# MWPR1516 register map
Vendor: Freescale Semiconductor, Inc.; Series: Kinetis; File version: 1.6
CPU: CM0PLUS r0p0, little endian, no MPU, no FPU, VTOR, 2 interrupt priority bits
Registers are 8-bit, read-write, reset 0x0 unless marked. A register's access mark holds for its fields unless they carry their own. Offsets are from the block's base; [hi:lo] are bit positions; {n}, {i} and the like mark numbered series; 'fields as' and 'values as' point back to an identical list.

## ICS — Clock management
Base 0x40064000; register names take the prefix ICS_
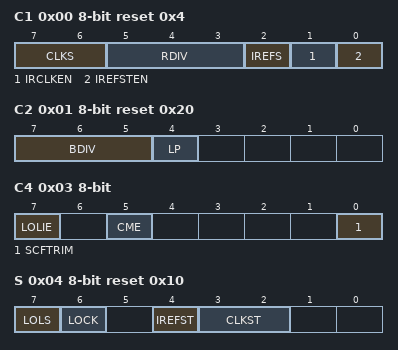
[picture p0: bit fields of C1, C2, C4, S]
0x00 C1 reset 0x4 — ICS Control Register 1
  [7:6] CLKS — Clock Source Select
    0=Output of FLL is selected; 1=Internal reference clock is selected; 2=External reference clock is selected; 3=Reserved, defaults to 00
  [5:3] RDIV — Reference Divider
  [2] IREFS — Internal Reference Select
    0=External reference clock is selected; 1=Internal reference clock is selected
  [1] IRCLKEN — Internal Reference Clock Enable
    0=ICSIRCLK is inactive; 1=ICSIRCLK is active
  [0] IREFSTEN — Internal Reference Stop Enable
    0=Internal reference clock is disabled in Stop mode; 1=Internal reference clock stays enabled in Stop mode if IRCLKEN is set, or if ICS is in FEI, FBI, or FBILP mode before entering Stop
0x01 C2 reset 0x20 — ICS Control Register 2
  [7:5] BDIV — Bus Frequency Divider
    0=Encoding 0-Divides the selected clock by 1; 1=Encoding 1-Divides the selected clock by 2 (reset default); 2=Encoding 2-Divides the selected clock by 4; 3=Encoding 3-Divides the selected clock by 8; 4=Encoding 4-Divides the selected clock by 16; 5=Encoding 5-Divides the selected clock by 32; 6=Encoding 6-Divides the selected clock by 64; 7=Encoding 7-Divides the selected clock by 128
  [4] LP — Low Power Select
    0=FLL is not disabled in bypass mode; 1=FLL is disabled in bypass modes unless debug is active
0x02 C3 reset not defined — ICS Control Register 3
  [7:0] SCTRIM — Slow Internal Reference Clock Trim Setting
0x03 C4 (reset mask 0xFE) — ICS Control Register 4
  [7] LOLIE — Loss of Lock Interrupt
    0=No request on loss of lock; 1=Generates an interrupt request on loss of lock
  [5] CME — Clock Monitor Enable
    0=Clock monitor is disabled; 1=Generates a reset request on loss of external clock
  [0] SCFTRIM — Slow Internal Reference Clock Fine Trim
0x04 S reset 0x10 — ICS Status Register
  [7] LOLS — Loss of Lock Status
    0=FLL has not lost lock since LOLS was last cleared; 1=FLL has lost lock since LOLS was last cleared
  [6] LOCK ro — Lock Status
    0=FLL is currently unlocked; 1=FLL is currently locked
  [4] IREFST ro — Internal Reference Status
    0=Source of reference clock is external clock; 1=Source of reference clock is internal clock
  [3:2] CLKST ro — Clock Mode Status
    0=Output of FLL is selected; 1=FLL Bypassed, internal reference clock is selected; 2=FLL Bypassed, external reference clock is selected

## OSC — Oscillator
Base 0x40065000; register names take the prefix OSC_
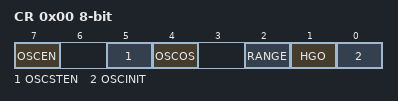
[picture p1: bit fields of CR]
0x00 CR — OSC Control Register
  [7] OSCEN — OSC Enable
    0=OSC module is disabled; 1=OSC module is enabled
  [5] OSCSTEN — OSC Enable in Stop mode
    0=OSC clock is disabled in Stop mode; 1=OSC clock stays enabled in Stop mode
  [4] OSCOS — OSC Output Select
    0=External clock source from EXTAL pin is selected; 1=Oscillator clock source is selected
  [2] RANGE — Frequency Range Select
    0=Low frequency range of 32 kHz; 1=High frequency range of 4-24 MHz
  [1] HGO — High Gain Oscillator Select
    0=Low-power mode; 1=High-gain mode
  [0] OSCINIT ro — OSC Initialization
    0=Oscillator initialization is not complete; 1=Oscillator initialization is completed

## LDO — Low Dropout Regulator
Base 0x40070000; register names take the prefix LDO_
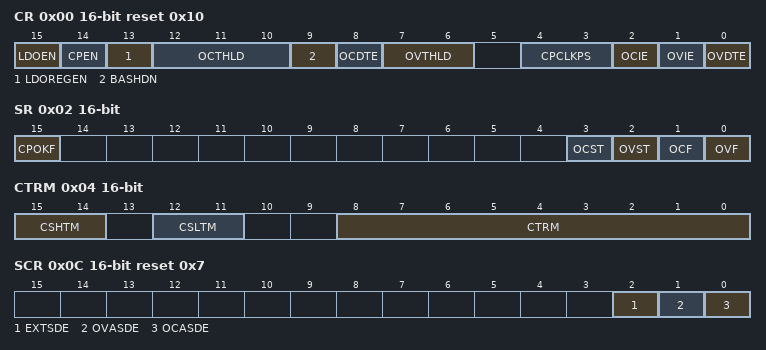
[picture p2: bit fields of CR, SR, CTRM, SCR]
0x00 CR 16-bit reset 0x10 — Control Register
  [15] LDOEN — LDO controller Enable
    0=LDO controller is disabled; 1=LDO controller is enabled
  [14] CPEN — Charge Pump Enable
    0=Charge pump is disabled; 1=Charge pump is enabled
  [13] LDOREGEN — LDO internal Regulator Enable
    0=LDO regulator is disabled; 1=LDO regulator is enabled
  [12:10] OCTHLD — Overcurrent Threshold Selection
    {v}=Level {v} (v=0..7)
  [9] BASHDN — Block the Automatic Shutdown
    0=Allows the automatically shutting down the power FET when OVP event occurs; 1=Blocks the automatic shutdown function from hard-block part when OVP event occurs. Software takes it over to shut down the external power FET.
  [8] OCDTE — Overcurrent Detection Enable
    0=Overcurrent detection is disabled; 1=Overcurrent detection is enabled
  [7:6] OVTHLD — Overvoltage Threshold Selection
    {v}=Level {v} (v=0..3)
  [4:3] CPCLKPS — Prescaler bits of the Clock to be divided for Charge Pump
    0=The division factor is 4; 1=The division factor is 8; 2=The division factor is 16; 3=The division factor is 32
  [2] OCIE — Overcurrent Interrupt Enable
    0=No interrupt gets asserted when the current loop output is over the current limit; 1=An interrupt gets asserted when the current loop output is over the current limit
  [1] OVIE — Overvoltage Interrupt Enable
    0=No interrupt gets asserted when the voltage loop output is over the voltage limit; 1=An interrupt gets asserted when the voltage loop output is over the voltage limit
  [0] OVDTE — Overvoltage Detection Enable
    0=Overvoltage detection is disabled; 1=Overvoltage detection is enabled
0x02 SR 16-bit — Status Register
  [15] CPOKF ro — Charge Pump OK status Flag
    0=Indicates the internal charge pump is not in OK status; 1=Indicates the internal charge pump is OK
  [3] OCST ro — Overcurrent Status
  [2] OVST ro — Overvoltage Status
  [1] OCF — Current loop Overcurrent Flag
    0=The current loop output is not over the current limit; 1=The current loop output is over the current limit
  [0] OVF — Voltage loop Overvoltage Flag
    0=The voltage loop output is not over the voltage limit; 1=The voltage loop output is over the voltage limit
0x04 CTRM 16-bit — Current Trim Register
  [15:14] CSHTM — Current Sensor High-side offset Trim
    0=0 mV; 1=3 mV; 2=6 mV; 3=9 mV
  [12:11] CSLTM — Current Sensor Low-side offset Trim
    0=0 mV; 1=3 mV; 2=6 mV; 3=9 mV
  [8:0] CTRM — Current loop configuration
0x06 VTRM 16-bit — Voltage Trim Register
  [8:0] VTRM — Voltage loop configuration
0x08 OCFILT 16-bit — Overcurrent Filter Register
  [15:0] CNT — Filter sample count for the overcurrent detection
    0=Filter is disabled. Overcurrent status is passing directly.
0x0A OVFILT 16-bit — Overvoltage Filter Register
  [15:0] CNT — Filter sample count for the overvoltage detection
    values as OCFILT.CNT
0x0C SCR 16-bit reset 0x7 — Shutdown Control Register
  [2] EXTSDE — External Shutdown Enable
    0=External shutdown request is disabled to turn off the LDO system; 1=External shutdown request is enabled to turn off the LDO system
  [1] OVASDE
    0=Voltage loop and current loop are not automatically shut down when the overvoltage happens; 1=Voltage loop and current loop are automatically shut down when the overvoltage happens
  [0] OCASDE
    0=Voltage loop and current loop are not automatically shut down when the overcurrent happens; 1=Voltage loop and current loop are automatically shut down when the overcurrent happens
